VERSION ""

NS_ :

BS_:
BU_: BRAKE STEERING THROTTLE FAULT STEERING_CTRL DIAGNOSTICS
BO_ 112 BRAKE_ENABLE: 8 BRAKE
   SG_ brake_enable_magic : 0|16@1+ (1,0) [0|0] "" BRAKE

BO_ 113 BRAKE_DISABLE: 8 BRAKE
   SG_ brake_disable_magic : 0|16@1+ (1,0) [0|0] "" BRAKE

BO_ 114 BRAKE_COMMAND: 8 BRAKE
   SG_ brake_command_magic : 0|16@1+ (1,0) [0|0] "" BRAKE
   SG_ brake_pedal_command : 16|32@1+ (1,0) [0|1] "percent" BRAKE

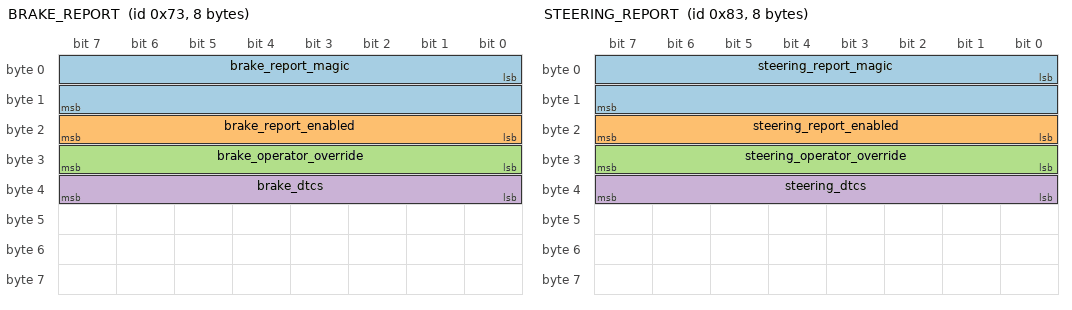
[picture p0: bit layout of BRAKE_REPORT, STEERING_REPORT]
BO_ 115 BRAKE_REPORT: 8 BRAKE
   SG_ brake_report_magic : 0|16@1+ (1,0) [0|0] "" BRAKE
   SG_ brake_report_enabled : 16|8@1+ (1,0) [0|0] "" BRAKE
   SG_ brake_operator_override : 24|8@1+ (1,0) [0|0] "" BRAKE
   SG_ brake_dtcs : 32|8@1+ (1,0) [0|0] "" BRAKE

BO_ 128 STEERING_ENABLE: 8 STEERING
   SG_ steering_enable_magic : 0|16@1+ (1,0) [0|0] "" STEERING

BO_ 129 STEERING_DISABLE: 8 STEERING
   SG_ steering_disable_magic : 0|16@1+ (1,0) [0|0] "" STEERING

BO_ 130 STEERING_TORQUE_COMMAND: 8 STEERING
   SG_ steering_command_magic : 0|16@1+ (1,0) [0|0] "" STEERING
   SG_ steering_torque_command : 16|32@1- (1,0) [-1|1] "percent" STEERING

BO_ 131 STEERING_REPORT: 8 STEERING
   SG_ steering_report_magic : 0|16@1+ (1,0) [0|0] "" STEERING
   SG_ steering_report_enabled : 16|8@1+ (1,0) [0|0] "" STEERING
   SG_ steering_operator_override : 24|8@1+ (1,0) [0|0] "" STEERING
   SG_ steering_dtcs : 32|8@1+ (1,0) [0|0] "" STEERING

BO_ 144 THROTTLE_ENABLE: 8 THROTTLE
   SG_ throttle_enable_magic : 0|16@1+ (1,0) [0|0] "" THROTTLE

BO_ 145 THROTTLE_DISABLE: 8 THROTTLE
   SG_ throttle_disable_magic : 0|16@1+ (1,0) [0|0] "" THROTTLE

BO_ 146 THROTTLE_COMMAND: 8 THROTTLE
   SG_ throttle_command_magic : 0|16@1+ (1,0) [0|0] "" THROTTLE
   SG_ throttle_pedal_command : 16|32@1+ (1,0) [0|1] "percent" THROTTLE

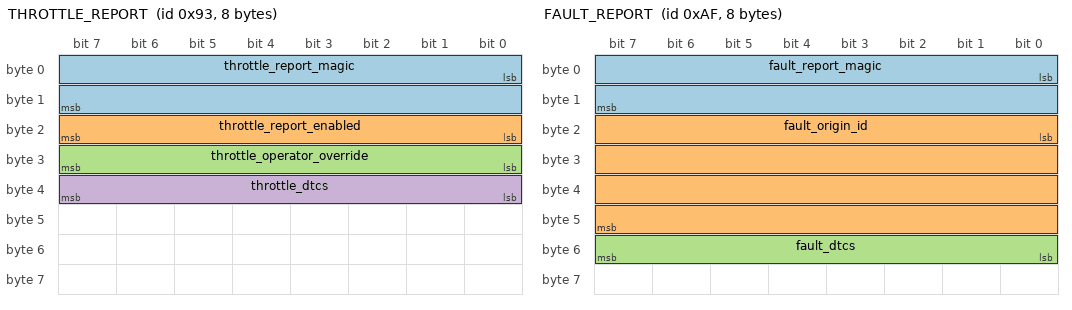
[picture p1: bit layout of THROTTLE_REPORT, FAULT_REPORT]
BO_ 147 THROTTLE_REPORT: 8 THROTTLE
   SG_ throttle_report_magic : 0|16@1+ (1,0) [0|0] "" THROTTLE
   SG_ throttle_report_enabled : 16|8@1+ (1,0) [0|0] "" THROTTLE
   SG_ throttle_operator_override : 24|8@1+ (1,0) [0|0] "" THROTTLE
   SG_ throttle_dtcs : 32|8@1+ (1,0) [0|0] "" THROTTLE

BO_ 175 FAULT_REPORT: 8 FAULT
   SG_ fault_report_magic : 0|16@1+ (1,0) [0|0] "" FAULT
   SG_ fault_origin_id : 16|32@1+ (1,0) [0|0] "" FAULT
   SG_ fault_dtcs : 48|8@1+ (1,0) [0|0] "" FAULT

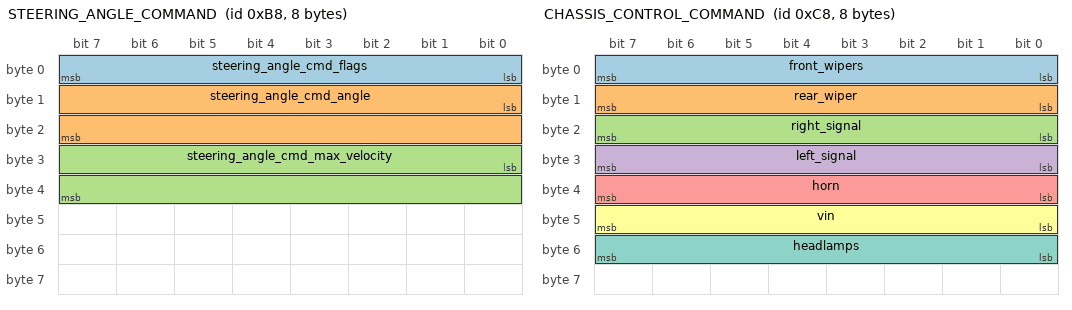
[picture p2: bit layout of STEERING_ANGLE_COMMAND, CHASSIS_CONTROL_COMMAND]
BO_ 184 STEERING_ANGLE_COMMAND: 8 STEERING_CTRL
   SG_ steering_angle_cmd_flags : 0|8@1+ (1,0) [0|0] "" STEERING_CTRL
   SG_ steering_angle_cmd_angle : 8|16@1- (0.1,0) [-600|600] "degrees" STEERING_CTRL
   SG_ steering_angle_cmd_max_velocity : 24|16@1- (0.1,0) [-0|800] "degrees/second" STEERING_CTRL

BO_ 185 STEERING_ANGLE_REPORT: 8 STEERING_CTRL
   SG_ steering_angle_report_flags : 0|8@1+ (1,0) [0|0] "" STEERING_CTRL
   SG_ steering_angle_report_errors : 8|8@1+ (1,0) [0|0] "" STEERING_CTRL

BO_ 200 CHASSIS_CONTROL_COMMAND: 8 DIAGNOSTICS
   SG_ front_wipers : 0|8@1+ (1,0) [0|0] "" DIAGNOSTICS
   SG_ rear_wiper : 8|8@1+ (1,0) [0|0] "" DIAGNOSTICS
   SG_ right_signal : 16|8@1+ (1,0) [0|0] "" DIAGNOSTICS
   SG_ left_signal : 24|8@1+ (1,0) [0|0] "" DIAGNOSTICS
   SG_ horn : 32|8@1+ (1,0) [0|0] "" DIAGNOSTICS
   SG_ vin : 40|8@1+ (1,0) [0|0] "" DIAGNOSTICS
   SG_ headlamps : 48|8@1+ (1,0) [0|0] "" DIAGNOSTICS

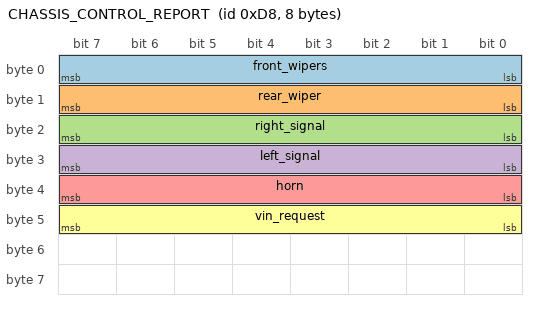
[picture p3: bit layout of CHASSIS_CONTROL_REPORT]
BO_ 216 CHASSIS_CONTROL_REPORT: 8 DIAGNOSTICS
   SG_ front_wipers : 0|8@1+ (1,0) [0|0] "" DIAGNOSTICS
   SG_ rear_wiper : 8|8@1+ (1,0) [0|0] "" DIAGNOSTICS
   SG_ right_signal : 16|8@1+ (1,0) [0|0] "" DIAGNOSTICS
   SG_ left_signal : 24|8@1+ (1,0) [0|0] "" DIAGNOSTICS
   SG_ horn : 32|8@1+ (1,0) [0|0] "" DIAGNOSTICS
   SG_ vin_request : 40|8@1+ (1,0) [0|0] "" DIAGNOSTICS

CM_ BU_ BRAKE "DriveKit braking control channel";
CM_ BU_ STEERING "DriveKit steering control channel";
CM_ BU_ THROTTLE "DriveKit throttle control channel";
CM_ BU_ FAULT "DriveKit fault reporting channel";
CM_ BU_ STEERING_CTRL "DriveKit angle-based steering control channel (experimental)";

CM_ BO_ 112 "Enable computer control of braking.";
VAL_ 112 brake_enable_magic 1372 "Default Magic Number";
CM_ BO_ 113 "Relinquish computer control of braking to operator.";
VAL_ 113 brake_disable_magic 1372 "Default Magic Number";
CM_ BO_ 114 "Set brake application percentage.";
VAL_ 114 brake_command_magic 1372 "Default Magic Number";
SIG_VALTYPE_ 114 brake_pedal_command : 1;
CM_ BO_ 115 "Periodically-transmitted braking control channel status.";
VAL_ 115 brake_report_magic 1372 "Default Magic Number";
VAL_ 115 brake_dtcs 0 "No communication with brake sensor" 1 "Operator Override: Brake";
VAL_ 115 brake_operator_override 0 "Not overridden by operator." 1 "Control overridden by operator.";
CM_ SG_ 115 brake_dtcs "Only valid when FAULT_REPORT (msg 175) is transmitted.";

CM_ BO_ 128 "Enable computer control of steering.";
VAL_ 128 steering_enable_magic 1372 "Default Magic Number";
CM_ BO_ 129 "Relinquish computer control of steering to operator.";
VAL_ 129 steering_disable_magic 1372 "Default Magic Number";
CM_ BO_ 130 "Set emulated operator steering torque.";
VAL_ 130 steering_command_magic 1372 "Default Magic Number";
CM_ SG_ 130 steering_torque_command "Emulated operator steering torque value. -1 full left, +1 full right.";
SIG_VALTYPE_ 130 steering_torque_command : 1;
CM_ BO_ 131 "Periodically-transmitted steering control channel status.";
VAL_ 131 steering_report_magic 1372 "Default Magic Number";
VAL_ 131 steering_report_enabled 0 "Disabled" 1 "Enabled";
VAL_ 131 steering_operator_override 0 "Not overridden by operator." 1 "Control overridden by operator.";
VAL_ 131 steering_dtcs 0 "No communication with steering sensor" 1 "Operator Override: Steering";
CM_ SG_ 131 steering_dtcs "Only valid when FAULT_REPORT (msg 175) is transmitted.";

CM_ BO_ 144 "Enable computer control of throttle.";
VAL_ 144 throttle_enable_magic 1372 "Default Magic Number";
CM_ BO_ 145 "Relinquish computer control of throttle to operator.";
VAL_ 145 throttle_disable_magic 1372 "Default Magic Number";
CM_ BO_ 146 "Set emulated acclerator pedal depression.";
VAL_ 146 throttle_command_magic 1372 "Default Magic Number";
CM_ SG_ 146 throttle_pedal_command "Emulated acclerator pedal depression percentage.";
SIG_VALTYPE_ 146 throttle_pedal_command : 1;
CM_ BO_ 147 "Periodically-transmitted throttle control channel status.";
VAL_ 147 throttle_report_magic 1372 "Default Magic Number";
VAL_ 147 throttle_report_enabled 0 "Disabled" 1 "Enabled";
VAL_ 147 throttle_operator_override 0 "Not overridden by operator." 1 "Control overridden by operator.";
VAL_ 147 throttle_dtcs 0 "No communication with steering sensor" 1 "Operator Override: Steering";
CM_ SG_ 147 throttle_dtcs "Only valid when FAULT_REPORT (msg 175) is transmitted.";

CM_ BO_ 175 "Report of a fault condition.";
VAL_ 175 fault_report_magic 1372 "Default Magic Number";
VAL_ 175 fault_origin_id 0 "brake control channel" 1 "steering control channel" 2 "throttle control channel";
CM_ SG_ 175 fault_dtcs "Corresponds to <channel>_dtcs signal values for channel indicated by fault_origin_id.";

CM_ BO_ 184 "Set desired steering angle and rate (experimental).";
VAL_ 184 steering_angle_cmd_flags 0 "Disabled" 1 "Enabled";
CM_ SG_ 184 steering_angle_cmd_angle "Commanded steering angle in degrees (-left, +right).";
CM_ SG_ 184 steering_angle_cmd_max_velocity "The maximum velocity at which the steering wheel should rotate.";
CM_ BO_ 185 "Periodically-transmitted steering angle controller report.";
VAL_ 185 steering_angle_report_flags 0 "Enable" 1 "Disable";
VAL_ 185 steering_angle_report_errors 6 "Command Rejected" 4 "Module Disabled" 2 "Angle Irrational" 1 "Angle Missing" 0 "None";

CM_ BO_ 200 "Control chassis features.";
VAL_ 200 front_wipers 0 "Do Nothing" 1 "Disable" 2 "Intermittent" 3 "Slow" 4 "Fast";
VAL_ 200 rear_wiper 0 "Do Nothing" 1 "Disable" 2 "Enable";
VAL_ 200 right_signal 0 "Do Nothing" 1 "Disable" 2 "Enable";
VAL_ 200 left_signal 0 "Do Nothing" 1 "Disable" 2 "Enable";
VAL_ 200 horn 0 "Do Nothing" 2 "Enabled";
VAL_ 200 vin 0 "Do Nothing" 2 "Requested";
VAL_ 200 headlamps 0 "Do Nothing" 1 "Disable" 2 "Low" 3 "High";

CM_ BO_ 216 "Periodically-transmitted chassis control report.";
VAL_ 216 front_wipers 0 "Disabled" 1 "Intermittent" 2 "Slow" 3 "Fast";
VAL_ 216 rear_wiper 0 "Disabled" 1 "Enabled";
VAL_ 216 right_signal 0 "Disabled" 1 "Enabled";
VAL_ 216 left_signal 0 "Disabled" 1 "Enabled";
VAL_ 216 horn 0 "Disabled" 1 "Enabled";
VAL_ 216 vin_request 0 "Disabled" 1 "Enabled";
VAL_ 216 headlamps 0 "Disabled" 1 "Low" 2 "High";
